# M051AN_v1 register map
File version: 1.0
Registers are 32-bit, read-write, reset 0x0 unless marked. A register's access mark holds for its fields unless they carry their own. Offsets are from the block's base; [hi:lo] are bit positions; {n}, {i} and the like mark numbered series; 'fields as' and 'values as' point back to an identical list.

## I2C — I2C Register Map
Base 0x40020000
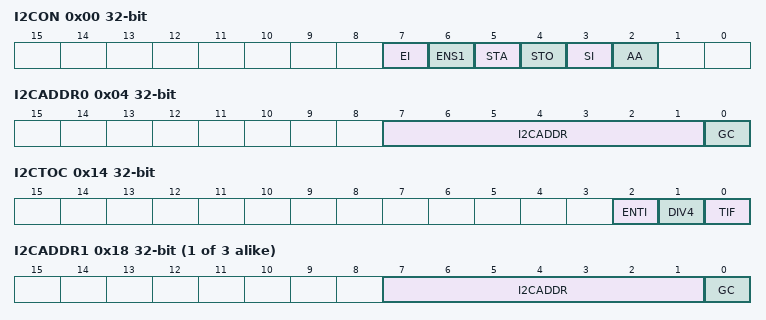
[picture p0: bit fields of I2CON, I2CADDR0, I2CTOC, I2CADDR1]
0x00 I2CON — I2C Control Register
  [7] EI — Enable Interrupt
    0=Disable I2C interrupt; 1=Enable I2C interrupt
  [6] ENS1 — I2C Controller Enable Bit
    0=Disable; 1=Enable
  [5] STA — I2C START Control Bit. Setting STA to logic 1 to enter master mode, the I2C hardware sends a START or repeat START condition to bus when the bus is free.
  [4] STO — I2C STOP Control Bit. In master mode, setting STO to transmit a STOP condition to bus then I2C hardware will check the bus condition if a STOP condition is detected this bit will be cleared by hardware automatically. In a slave mode, setting STO resets I2C hardware to the defined "not addressed" slave mode. This means it is NO LONGER in the slave receiver mode to receive data from the master transmit device.
  [3] SI — I2C Interrupt Flag. When a new I2C state is present in the I2CSTATUS register, the SI flag is set by hardware, and if bit EI (I2CON [7]) is set, the I2C interrupt is requested. SI must be cleared by software. Clear SI is by writing one to this bit.
  [2] AA — Assert Acknowledge Control Bit
0x04 I2CADDR0 — I2C Slave Address Register0
  [7:1] I2CADDR — I2C Address Register. The content of this register is irrelevant when I2C is in master mode. In the slave mode, the seven most significant bits must be loaded with the MCU's own address. The I2C hardware will react if either of the address is matched.
  [0] GC — General Call Function
    0=Disable General Call Function; 1=Enable General Call Function
0x08 I2CDAT — I2C DATA Register
  [7:0] I2CDAT — I2C Data Register. Bit [7:0] is located with the 8-bit transferred data of I2C serial port.
0x0C I2CSTATUS ro reset 0xF8
  [7:0] I2CSTATUS — I2C Status Register. The status register of I2C:
0x10 I2CLK — I2C Clock Divided Register
  [7:0] I2CLK — I2C clock divided Register
0x14 I2CTOC — I2C Timeout Control Register
  [2] ENTI — Time-out counter is enabled/disable. When Enable, the 14 bit time-out counter will start counting when SI is clear. Setting flag SI to high will reset counter and re-start up counting after SI is cleared.
    0=Disable; 1=Enable
  [1] DIV4 — Time-Out counter input clock is divided by 4. When Enable, The time-Out period is extend 4 times.
    0=Disable; 1=Enable
  [0] TIF — Time-Out Flag
    0=S/W can clear the flag; 1=Time-Out flag is set by H/W. It can interrupt CPU
{0x14+4i} I2CADDR{i} (i=1..3) — I2C Slave Address Register{i}
  fields as I2CADDR0
{0x24+4i} I2CADM{i} (i=0..3) — I2C Slave Address Mask Register{i}
  [7:1] I2CADMx — I2C Address Mask register. I2C bus controllers support multiple address recognition with four address mask register. When the bit in the address mask register is set to one, it means the received corresponding address bit is don't-care. If the bit is set to zero, that means the received corresponding register bit should be exact the same as address register.
    0=Mask disable (the received corresponding register bit should be exact the same as address register.); 1=Mask enable (the received corresponding address bit is don't care.)

## TMR01 — TIMER Register Map
Base 0x40010000
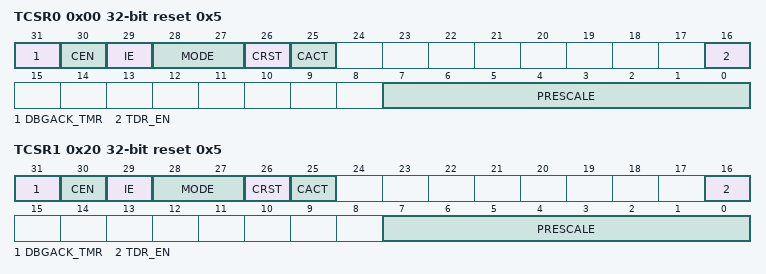
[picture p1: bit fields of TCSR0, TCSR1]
0x00 TCSR0 reset 0x5 — Timer0 Control and Status Register
  [31] DBGACK_TMR — ICE debug mode acknowledge Disable (write-protected). TIMER counter will be held while ICE debug mode acknowledged.
    0=ICE debug mode acknowledgement effects TIMER counting; 1=ICE debug mode acknowledgement disabled
  [30] CEN — Timer Enable Bit
    0=Stops/Suspends counting; 1=Starts counting
  [29] IE — Interrupt Enable Bit. If timer interrupt is enabled, the timer asserts its interrupt signal when the associated timer is equal to TCMPR.
    0=Disable timer Interrupt; 1=Enable timer Interrupt
  [28:27] MODE — Timer Operating Mode
  [26] CRST — Timer Reset Bit. Set this bit will reset the 24-bit up-timer, 8-bit pre-scale counter and also force CEN to 0.
    0=No effect; 1=Reset Timer's 8-bit pre-scale counter, internal 24-bit up-timer and CEN bit
  [25] CACT ro — Timer Active Status Bit (Read only). This bit indicates the status of timer.
    0=Timer is not active; 1=Timer is active
  [16] TDR_EN — Data Load Enable. When TDR_EN is set, TDR (Timer Data Register) will be updated continuously with the 24-bit up-timer value.
    0=Timer Data Register update disable; 1=Timer Data Register update enable
  [7:0] PRESCALE — Pre-scale Counter
0x04 TCMPR0 — Timer0 Compare Register
  [23:0] TCMP — Timer Compared Value. Note1: Never write 0x0 or 0x1 in TCMP, or the core will run into unknown state. Note2: When timer is operating at continuous counting mode, the 24-bit up-timer will count continuously if software writes a new value into TCMP. If timer is operating at other modes, the 24-bit up-timer will restart counting and using newest TCMP value to be the compared value if software writes a new value into TCMP.
0x08 TISR0 — Timer0 Interrupt Status Register
  [0] TIF — Timer Interrupt Flag. This bit indicates the interrupt status of Timer. TIF bit is set by hardware when the up counting value of internal 24-bit timer matches the timer compared value (TCMP). It is cleared by writing 1 to this bit.
0x0C TDR0 ro — Timer0 Data Register
  [23:0] TDR — Timer Data Register. When TCSR.TDR_EN is set to 1, the internal 24-bit up-timer value will be loaded into TDR. User can read this register for the up-timer value.
0x20 TCSR1 reset 0x5 — Timer1 Control and Status Register
  fields as TCSR0
0x24 TCMPR1 — Timer1 Compare Register
  fields as TCMPR0
0x28 TISR1 — Timer1 Interrupt Status Register
  fields as TISR0
0x2C TDR1 ro — Timer1 Data Register
  fields as TDR0
